# N32G033 register map
Vendor: Nsingtech Ltd.; File version: 1.0
Registers are 32-bit, read-write, reset 0x0 unless marked. A register's access mark holds for its fields unless they carry their own. Offsets are from the block's base; [hi:lo] are bit positions; {n}, {i} and the like mark numbered series.

## TIM3
Base 0x40000400
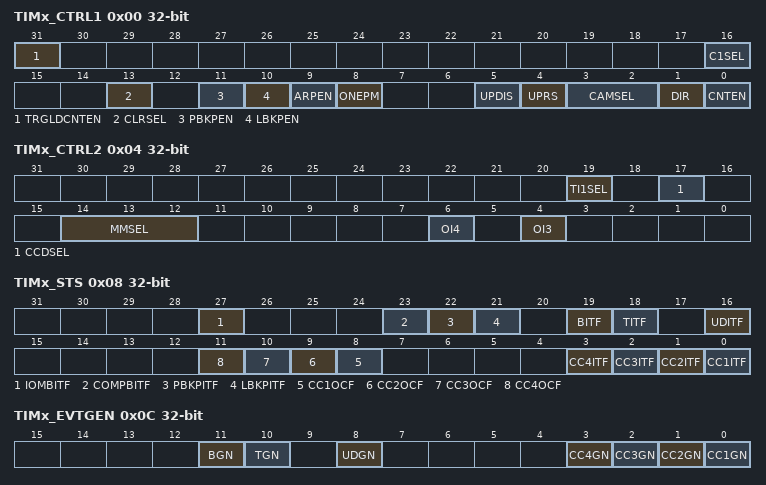
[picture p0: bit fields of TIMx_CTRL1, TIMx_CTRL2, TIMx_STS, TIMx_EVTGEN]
0x00 TIMx_CTRL1 — GTIM control register1
  [31] TRGLDCNTEN, [16] C1SEL, [13] CLRSEL, [11] PBKPEN, [10] LBKPEN, [9] ARPEN, [8] ONEPM, [5] UPDIS, [4] UPRS, [3:2] CAMSEL, [1] DIR, [0] CNTEN
0x04 TIMx_CTRL2 — GTIM control register2
  [19] TI1SEL, [17] CCDSEL, [14:12] MMSEL, [6] OI4, [4] OI3
0x08 TIMx_STS — GTIM status register
  [27] IOMBITF, [23] COMPBITF, [22] PBKPITF, [21] LBKPITF, [19] BITF, [18] TITF, [16] UDITF, [n+7] CC{n}OCF (n=1..4), [n-1] CC{n}ITF (n=1..4)
0x0C TIMx_EVTGEN — GTIM event generation register
  [11] BGN, [10] TGN, [8] UDGN, [n-1] CC{n}GN (n=1..4)
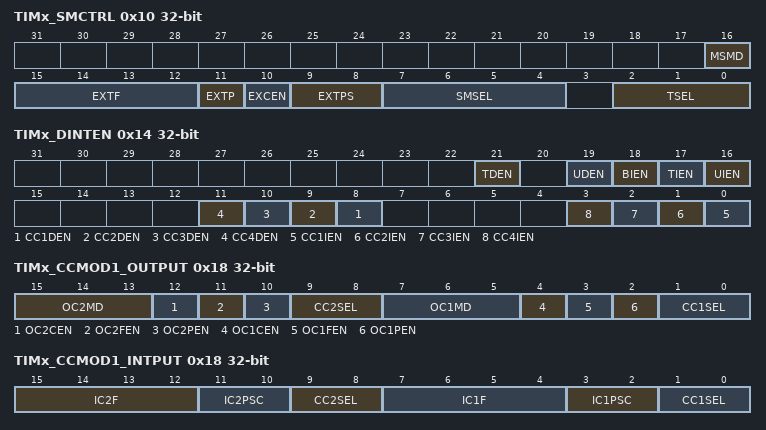
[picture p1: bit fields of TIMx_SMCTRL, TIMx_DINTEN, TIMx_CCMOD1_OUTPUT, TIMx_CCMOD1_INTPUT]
0x10 TIMx_SMCTRL — GTIM slave mode control register
  [16] MSMD, [15:12] EXTF, [11] EXTP, [10] EXCEN, [9:8] EXTPS, [7:4] SMSEL, [2:0] TSEL
0x14 TIMx_DINTEN — GTIM DMA/Interrupt enable register
  [21] TDEN, [19] UDEN, [18] BIEN, [17] TIEN, [16] UIEN, [n+7] CC{n}DEN (n=1..4), [n-1] CC{n}IEN (n=1..4)
0x18 TIMx_CCMOD1_OUTPUT — TIM capture/compare mode register 1 (output mode)
  [15:13] OC2MD, [12] OC2CEN, [11] OC2FEN, [10] OC2PEN, [9:8] CC2SEL, [7:5] OC1MD, [4] OC1CEN, [3] OC1FEN, [2] OC1PEN, [1:0] CC1SEL
0x18 TIMx_CCMOD1_INTPUT (alternate view of TIMx_CCMOD1_OUTPUT) — TIM capture/compare mode register 1 (intput mode)
  [15:12] IC2F, [11:10] IC2PSC, [9:8] CC2SEL, [7:4] IC1F, [3:2] IC1PSC, [1:0] CC1SEL
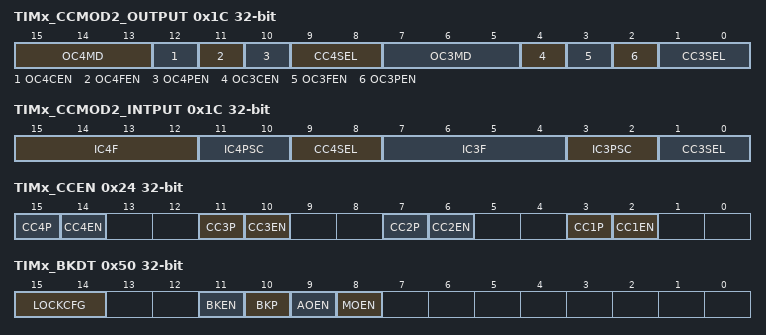
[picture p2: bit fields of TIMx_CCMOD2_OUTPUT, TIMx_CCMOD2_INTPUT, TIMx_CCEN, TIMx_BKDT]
0x1C TIMx_CCMOD2_OUTPUT — TIM capture/compare mode register 2 (output mode)
  [15:13] OC4MD, [12] OC4CEN, [11] OC4FEN, [10] OC4PEN, [9:8] CC4SEL, [7:5] OC3MD, [4] OC3CEN, [3] OC3FEN, [2] OC3PEN, [1:0] CC3SEL
0x1C TIMx_CCMOD2_INTPUT (alternate view of TIMx_CCMOD2_OUTPUT) — TIM capture/compare mode register 2 (intput mode)
  [15:12] IC4F, [11:10] IC4PSC, [9:8] CC4SEL, [7:4] IC3F, [3:2] IC3PSC, [1:0] CC3SEL
0x24 TIMx_CCEN — GTIM capture/compare enable register
  [4n-1] CC{n}P (n=1..4), [4n-2] CC{n}EN (n=1..4)
{0x24+4i} TIMx_CCDAT{i} (i=1..4) — GTIM capture/compare register {i}
  [15:0] CCDAT{i}
0x40 TIMx_PSC — GTIM prescaler register
  [15:0] PSC
0x44 TIMx_ARR reset 0xFFFF — GTIM auto-reload register
  [15:0] ARR
0x48 TIMx_CNT — GTIM counter register
  [15:0] CNT
0x50 TIMx_BKDT — TIM Break and Deadtime control register
  [15:14] LOCKCFG, [11] BKEN, [10] BKP, [9] AOEN, [8] MOEN
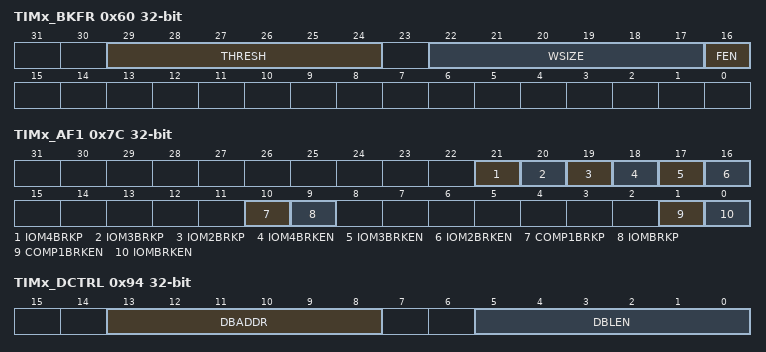
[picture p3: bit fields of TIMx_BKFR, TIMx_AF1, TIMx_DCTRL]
0x60 TIMx_BKFR — TIM break 1 Filter
  [29:24] THRESH, [22:17] WSIZE, [16] FEN
0x7C TIMx_AF1 — TIM AF1
  [21] IOM4BRKP, [20] IOM3BRKP, [19] IOM2BRKP, [18] IOM4BRKEN, [17] IOM3BRKEN, [16] IOM2BRKEN, [10] COMP1BRKP, [9] IOMBRKP, [1] COMP1BRKEN, [0] IOMBRKEN
0x90 TIMx_ENCMLV — GTIM Load Value (LVR) of counter register
  [15:0] LVR
0x94 TIMx_DCTRL — GTIM DMA control register
  [13:8] DBADDR, [5:0] DBLEN
0x98 TIMx_DADDR — GTIM DMA address for full transfer
  [31:0] BURST

## TIM4
Base 0x40013400
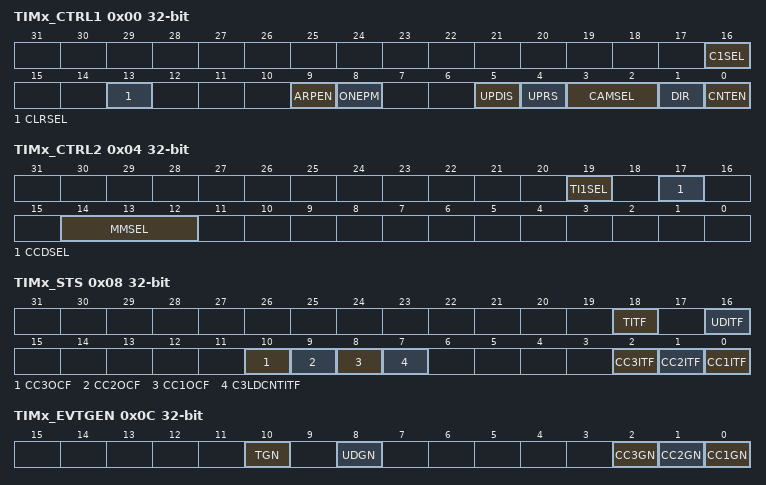
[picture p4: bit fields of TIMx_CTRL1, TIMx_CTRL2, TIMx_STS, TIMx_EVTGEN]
0x00 TIMx_CTRL1 — GTIM control register1
  [16] C1SEL, [13] CLRSEL, [9] ARPEN, [8] ONEPM, [5] UPDIS, [4] UPRS, [3:2] CAMSEL, [1] DIR, [0] CNTEN
0x04 TIMx_CTRL2 — GTIM control register2
  [19] TI1SEL, [17] CCDSEL, [14:12] MMSEL
0x08 TIMx_STS — GTIM status register
  [18] TITF, [16] UDITF, [10] CC3OCF, [9] CC2OCF, [8] CC1OCF, [7] C3LDCNTITF, [2] CC3ITF, [1] CC2ITF, [0] CC1ITF
0x0C TIMx_EVTGEN — GTIM event generation register
  [10] TGN, [8] UDGN, [2] CC3GN, [1] CC2GN, [0] CC1GN
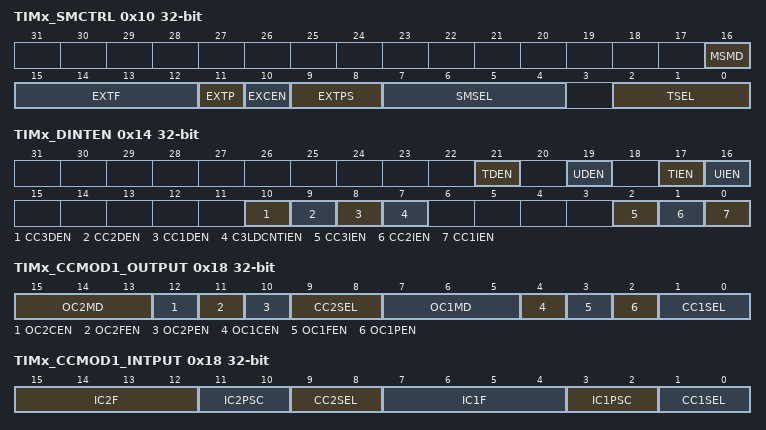
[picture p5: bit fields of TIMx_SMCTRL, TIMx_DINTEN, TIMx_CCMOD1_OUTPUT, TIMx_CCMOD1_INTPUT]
0x10 TIMx_SMCTRL — GTIM slave mode control register
  [16] MSMD, [15:12] EXTF, [11] EXTP, [10] EXCEN, [9:8] EXTPS, [7:4] SMSEL, [2:0] TSEL
0x14 TIMx_DINTEN — GTIM DMA/Interrupt enable register
  [21] TDEN, [19] UDEN, [17] TIEN, [16] UIEN, [10] CC3DEN, [9] CC2DEN, [8] CC1DEN, [7] C3LDCNTIEN, [2] CC3IEN, [1] CC2IEN, [0] CC1IEN
0x18 TIMx_CCMOD1_OUTPUT — TIM capture/compare mode register 1 (output mode)
  [15:13] OC2MD, [12] OC2CEN, [11] OC2FEN, [10] OC2PEN, [9:8] CC2SEL, [7:5] OC1MD, [4] OC1CEN, [3] OC1FEN, [2] OC1PEN, [1:0] CC1SEL
0x18 TIMx_CCMOD1_INTPUT (alternate view of TIMx_CCMOD1_OUTPUT) — TIM capture/compare mode register 1 (intput mode)
  [15:12] IC2F, [11:10] IC2PSC, [9:8] CC2SEL, [7:4] IC1F, [3:2] IC1PSC, [1:0] CC1SEL
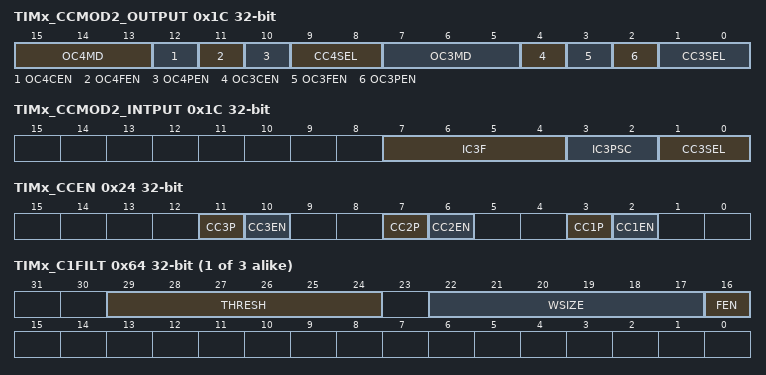
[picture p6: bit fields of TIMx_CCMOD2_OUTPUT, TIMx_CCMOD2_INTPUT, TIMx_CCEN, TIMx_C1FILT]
0x1C TIMx_CCMOD2_OUTPUT — TIM capture/compare mode register 2 (output mode)
  [15:13] OC4MD, [12] OC4CEN, [11] OC4FEN, [10] OC4PEN, [9:8] CC4SEL, [7:5] OC3MD, [4] OC3CEN, [3] OC3FEN, [2] OC3PEN, [1:0] CC3SEL
0x1C TIMx_CCMOD2_INTPUT (alternate view of TIMx_CCMOD2_OUTPUT) — TIM capture/compare mode register 2 (intput mode)
  [7:4] IC3F, [3:2] IC3PSC, [1:0] CC3SEL
0x24 TIMx_CCEN — GTIM capture/compare enable register
  [11] CC3P, [10] CC3EN, [7] CC2P, [6] CC2EN, [3] CC1P, [2] CC1EN
{0x24+4i} TIMx_CCDAT{i} (i=1..3) — GTIM capture/compare register {i}
0x40 TIMx_PSC — GTIM prescaler register
  [15:0] PSC
0x44 TIMx_ARR reset 0xFFFFFFFF — GTIM auto-reload register
0x48 TIMx_CNT — GTIM counter register
{0x60+4i} TIMx_C{i}FILT (i=1..3) — GTIM channal {i} input Filter
  [29:24] THRESH, [22:17] WSIZE, [16] FEN
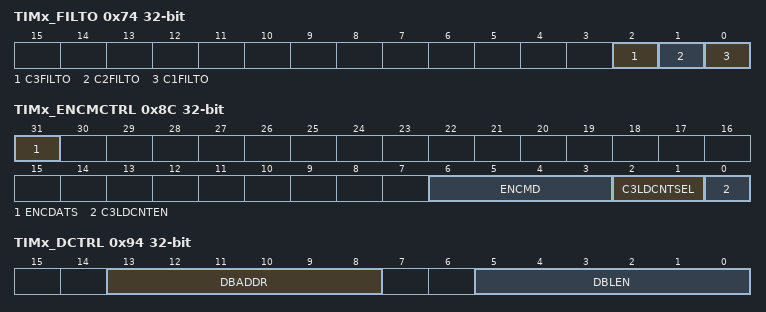
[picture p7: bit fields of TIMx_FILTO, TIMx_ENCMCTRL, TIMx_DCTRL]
0x74 TIMx_FILTO — GTIM channel filter output
  [2] C3FILTO, [1] C2FILTO, [0] C1FILTO
0x88 TIMx_ENCDAT — GTIM encoder capture data register.
0x8C TIMx_ENCMCTRL — GTIM encoder mode conctrl register
  [31] ENCDATS, [6:3] ENCMD, [2:1] C3LDCNTSEL, [0] C3LDCNTEN
0x90 TIMx_ENCLVR — GTIM Load Value (LVR) of counter register
  [31:0] LVR
0x94 TIMx_DCTRL — GTIM DMA control register
  [13:8] DBADDR, [5:0] DBLEN
0x98 TIMx_DADDR — GTIM DMA address for full transfer
  [31:0] BURST

## TIM6
Base 0x40001000
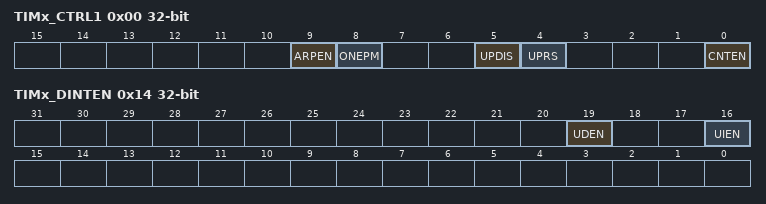
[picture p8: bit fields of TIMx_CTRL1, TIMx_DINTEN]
0x00 TIMx_CTRL1 — TIM control register1
  [9] ARPEN, [8] ONEPM, [5] UPDIS, [4] UPRS, [0] CNTEN
0x08 TIMx_STS — TIM status register
  [16] UDITF
0x0C TIMx_EVTGEN — TIM event generation register
  [8] UDGN
0x14 TIMx_DINTEN — TIM DMA/Interrupt enable register
  [19] UDEN, [16] UIEN
0x40 TIMx_PSC — TIM prescaler register
  [15:0] PSC
0x44 TIMx_AR reset 0xFFFFFFFF — TIM auto-reload register
0x48 TIMx_CNT — TIM counter register
